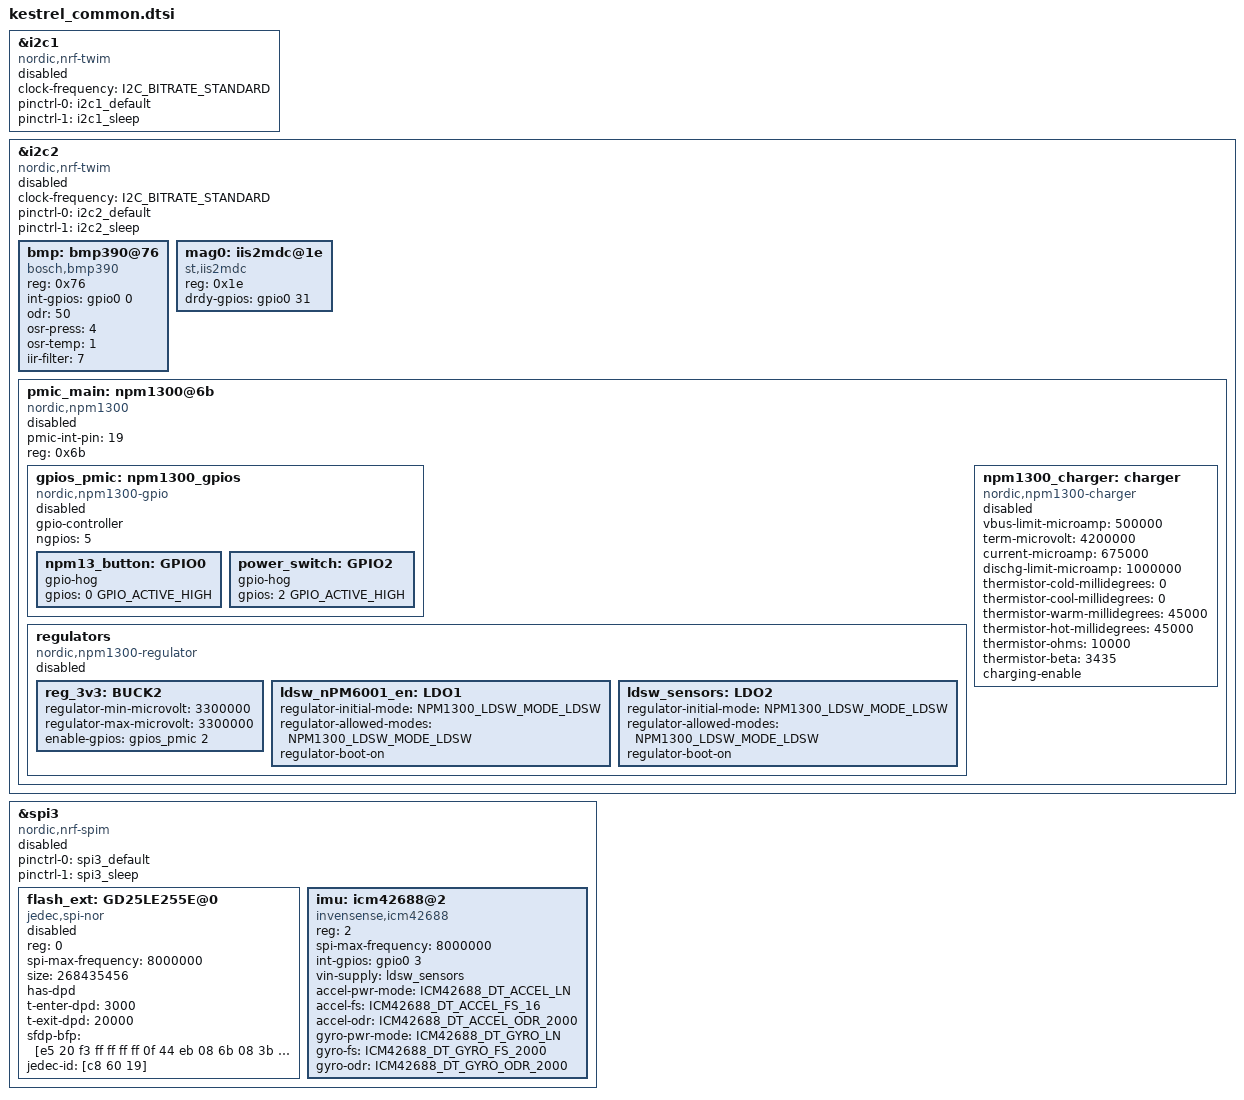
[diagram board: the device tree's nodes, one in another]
/*
 * Copyright (c) 2024 Nordic Semiconductor
 * SPDX-License-Identifier: LicenseRef-Nordic-5-Clause
 */

#include <dt-bindings/regulator/npm1300.h>
#include <zephyr/dt-bindings/sensor/icm42688.h>
/* I2C1 for LED control */
&i2c1 {
	compatible = "nordic,nrf-twim";
	status = "disabled";
	clock-frequency = <I2C_BITRATE_STANDARD>;

	pinctrl-0 = <&i2c1_default>;
	pinctrl-1 = <&i2c1_sleep>;
	pinctrl-names = "default", "sleep";
};



&i2c2 {
	compatible = "nordic,nrf-twim";
	status = "disabled";
	clock-frequency = <I2C_BITRATE_STANDARD>;
	
	pinctrl-0 = <&i2c2_default>;
	pinctrl-1 = <&i2c2_sleep>;
	pinctrl-names = "default", "sleep";

	bmp: bmp390@76 {
        compatible = "bosch,bmp390";
        reg = <0x76>;
        status = "okay";
        int-gpios = <&gpio0 0 GPIO_ACTIVE_HIGH>;
        odr = "50";      
        osr-press = <4>;     
        osr-temp  = <1>;    
        iir-filter = <7>;   
    };

	mag0: iis2mdc@1e {
        compatible = "st,iis2mdc";
        reg = <0x1e>;
        status = "okay";
        drdy-gpios = <&gpio0 31 GPIO_ACTIVE_HIGH>;

    };

	pmic_main: npm1300@6b {
		compatible = "nordic,npm1300";
		status = "disabled";
		pmic-int-pin = <19>;
		reg = <0x6b>;

		
		gpios_pmic: npm1300_gpios {
			compatible = "nordic,npm1300-gpio";
			status = "disabled";
			gpio-controller;
			#gpio-cells = <2>;
			ngpios = <5>;
			npm13_button: GPIO0 {
				gpio-hog;
				gpios = <0 GPIO_ACTIVE_HIGH>;
			};
		
			power_switch: GPIO2 {
				gpio-hog;
				gpios = <2 GPIO_ACTIVE_HIGH>;
			};
			
		};

		regulators {
			compatible = "nordic,npm1300-regulator";
			status = "disabled";
			/* Main 3.3 V regulator, enabled by GPIO2 (power switch) */
			reg_3v3: BUCK2 {
				regulator-min-microvolt = <3300000>;
				regulator-max-microvolt = <3300000>;
				enable-gpios = <&gpios_pmic 2 GPIO_ACTIVE_HIGH>;
			};
			/* LDO1 is used as a load switch pulling the nPM6001 enable line to VSYS */
			ldsw_nPM6001_en: LDO1 {
				regulator-initial-mode = <NPM1300_LDSW_MODE_LDSW>;
				regulator-allowed-modes = <NPM1300_LDSW_MODE_LDSW>;
				regulator-boot-on;
			};
			/* LDO2 is used as a load switch for sensor power supply */
			ldsw_sensors: LDO2 {
				regulator-initial-mode = <NPM1300_LDSW_MODE_LDSW>;
				regulator-allowed-modes = <NPM1300_LDSW_MODE_LDSW>;
				regulator-boot-on;
			};
		};

		npm1300_charger: charger {
			compatible = "nordic,npm1300-charger";
			status = "disabled";
			vbus-limit-microamp = <500000>;
			/* Battery specs from LiPol LP803448 datasheet (Dwg. nr. FD_3245_70) */
			term-microvolt = <4200000>;
			current-microamp = <675000>; /* 0.5C charging current */
			dischg-limit-microamp = <1000000>; /* Maximum value for PMIC */
			thermistor-cold-millidegrees = <0>;
			thermistor-cool-millidegrees = <0>;
			thermistor-warm-millidegrees = <45000>;
			thermistor-hot-millidegrees = <45000>;
			thermistor-ohms = <10000>;
			thermistor-beta = <3435>;
			charging-enable;
		};
	};

	


};

&spi3 {
	compatible = "nordic,nrf-spim";
	status = "disabled";

	pinctrl-0 = <&spi3_default>;
	pinctrl-1 = <&spi3_sleep>;
	pinctrl-names = "default", "sleep";

	flash_ext: GD25LE255E@0 {
		compatible = "jedec,spi-nor";
		status = "disabled";
		reg = <0>;
		spi-max-frequency = <8000000>;
		size = <268435456>;
		has-dpd;
		t-enter-dpd = <3000>;
		t-exit-dpd = <20000>;
		sfdp-bfp = [e5 20 f3 ff  ff ff ff 0f  44 eb 08 6b  08 3b 42 bb
			    fe ff ff ff  ff ff 00 ff  ff ff 42 eb  0c 20 0f 52
			    10 d8 00 ff  d4 31 a5 fe  84 df 14 4f  ec 62 16 33
			    7a 75 7a 75  04 b3 d5 5c  19 06 14 00  08 50 00 01];
		jedec-id = [c8 60 19];
	};

	imu: icm42688@2 {
        compatible = "invensense,icm42688";
        reg = <2>;                       
        spi-max-frequency = <8000000>;
        status = "okay";
        int-gpios = <&gpio0 3 GPIO_ACTIVE_HIGH>;
		vin-supply = <&ldsw_sensors>;

		accel-pwr-mode = <ICM42688_DT_ACCEL_LN>;
		accel-fs = <ICM42688_DT_ACCEL_FS_16>;
		accel-odr = <ICM42688_DT_ACCEL_ODR_2000>;
		gyro-pwr-mode= <ICM42688_DT_GYRO_LN>;
		gyro-fs = <ICM42688_DT_GYRO_FS_2000>;
		gyro-odr = <ICM42688_DT_GYRO_ODR_2000>;
    };

};
